AUTOSAR XML (schema 00046)
package /LedControl_SWC_2_package
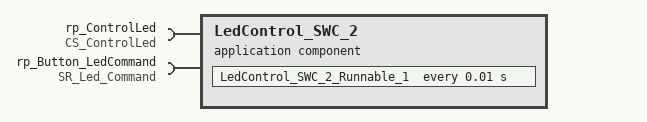
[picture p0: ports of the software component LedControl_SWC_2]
  application sw component type LedControl_SWC_2
    require port rp_ControlLed: client-com-spec=CS_ControlLed_Operation_1, required-interface=CS_ControlLed
    require port rp_Button_LedCommand: nonqueued-receiver-com-spec{data-element=SR_Led_Command_Element_1, init-value=SR_Led_Command_Element_1:0}, required-interface=SR_Led_Command
    behavior LedControl_SWC_2_internal_behavior
      timing event Periodic_Event_2_event: start-on-event=LedControl_SWC_2_Runnable_1, period=0.01
      runnable LedControl_SWC_2_Runnable_1
        data-read-access:
          access LedControl_SWC_2_Runnable_1_rp_Button_LedCommand_SR_Led_Command_Element_1: accessed-variable=rp_Button_LedCommand.SR_Led_Command_Element_1
        sync call LedControl_SWC_2_Runnable_1_rp_ControlLed_CS_ControlLed_Operation_1: operation=rp_ControlLed.CS_ControlLed_Operation_1
